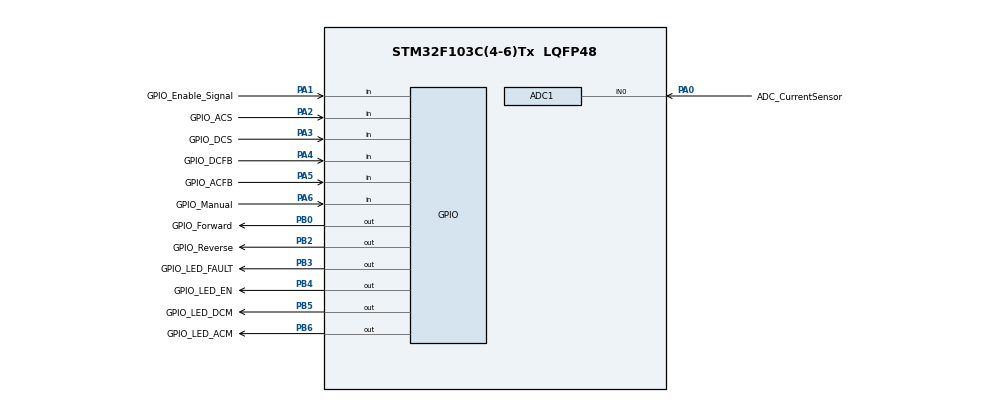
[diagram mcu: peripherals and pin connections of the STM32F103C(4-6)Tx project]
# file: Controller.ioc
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ADC1.EnableAnalogWatchDog=false
ADC1.NbrOfConversionFlag=1
ADC1.master=1
IWDG.Prescaler=IWDG_PRESCALER_64
Mcu.Family=STM32F1
Mcu.Name=STM32F103C(4-6)Tx
Mcu.Package=LQFP48
NVIC.ADC1_2_IRQn=true\:0\:0\:false\:false\:true\:true\:true\:true
NVIC.PriorityGroup=NVIC_PRIORITYGROUP_4
PA0-WKUP.GPIO_Label=ADC_CurrentSensor
PA0-WKUP.GPIO_Mode=GPIO_MODE_ANALOG
PA0-WKUP.Signal=ADCx_IN0
PA1.GPIO_Label=GPIO_Enable_Signal
PA1.Signal=GPIO_Input
PA13.Signal=SYS_JTMS-SWDIO
PA14.Signal=SYS_JTCK-SWCLK
PA15.Signal=S_TIM2_CH1_ETR
PA2.GPIO_Label=GPIO_ACS
PA2.Signal=GPIO_Input
PA3.GPIO_Label=GPIO_DCS
PA3.Signal=GPIO_Input
PA4.GPIO_Label=GPIO_DCFB
PA4.Signal=GPIO_Input
PA5.GPIO_Label=GPIO_ACFB
PA5.Signal=GPIO_Input
PA6.GPIO_Label=GPIO_Manual
PA6.Signal=GPIO_Input
PB0.GPIO_Label=GPIO_Forward
PB0.Signal=GPIO_Output
PB2.GPIO_Label=GPIO_Reverse
PB2.Signal=GPIO_Output
PB3.GPIO_Label=GPIO_LED_FAULT
PB3.Signal=GPIO_Output
PB4.GPIO_Label=GPIO_LED_EN
PB4.Signal=GPIO_Output
PB5.GPIO_Label=GPIO_LED_DCM
PB5.Signal=GPIO_Output
PB6.GPIO_Label=GPIO_LED_ACM
PB6.Signal=GPIO_Output
PD0-OSC_IN.Mode=HSE-External-Oscillator
PD0-OSC_IN.Signal=RCC_OSC_IN
PD1-OSC_OUT.Mode=HSE-External-Oscillator
PD1-OSC_OUT.Signal=RCC_OSC_OUT
ProjectManager.HeapSize=0x200
ProjectManager.StackSize=0x400
ProjectManager.TargetToolchain=STM32CubeIDE
SH.ADCx_IN0.0=ADC1_IN0,IN0
SH.S_TIM2_CH1_ETR.0=TIM2_CH1
VP_IWDG_VS_IWDG.Mode=IWDG_Activate
VP_SYS_VS_ND.Mode=No_Debug
VP_TIM2_VS_ClockSourceINT.Mode=Internal
board=custom

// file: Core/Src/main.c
/* USER CODE BEGIN Header */
/**
 ******************************************************************************
 * @file           : main.c
 * @brief          : Main program body
 ******************************************************************************
 * @attention
 *
 * Copyright (c) 2024 STMicroelectronics.
 * All rights reserved.
 *
 * This software is licensed under terms that can be found in the LICENSE file
 * in the root directory of this software component.
 * If no LICENSE file comes with this software, it is provided AS-IS.
 *
 ******************************************************************************
 */
/* USER CODE END Header */
#include "main.h"
#include "fault_handling.h"
#include "QS_Switch.h"

/* USER CODE BEGIN PTD */
// Global Variables
volatile uint32_t timer_ms = 0;
volatile uint8_t es_active = 0;
volatile uint8_t dcs_active = 0;
volatile uint8_t acs_active = 0;
volatile uint8_t fault_state = 0;
volatile uint8_t manual_mode = 0;
volatile uint8_t current_mode = 0; // 0: None, 1: DC, 2: AC

/* USER CODE END PTD */

/* USER CODE BEGIN PD */
// Function Prototypes
/* USER CODE END PD */

ADC_HandleTypeDef hadc1;

IWDG_HandleTypeDef hiwdg;

TIM_HandleTypeDef htim2;

void SystemClock_Config(void);
static void MX_GPIO_Init(void);
static void MX_ADC1_Init(void);
static void MX_TIM2_Init(void);
static void MX_IWDG_Init(void);

int main(void)
    {

    /* MCU Configuration--------------------------------------------------------*/

    /* Reset of all peripherals, Initializes the Flash interface and the Systick. */
    HAL_Init();

    /* Configure the system clock */
    SystemClock_Config();

    /* Initialize all configured peripherals */
    MX_GPIO_Init();
    MX_ADC1_Init();
    MX_TIM2_Init();
    MX_IWDG_Init();
    HAL_GPIO_WritePin(GPIOB, GPIO_LED_EN_Pin, GPIO_PIN_SET);
    /* Infinite loop */
    while (1)
	{
	RunQSLoop();
	}
    }

void SystemClock_Config(void)
    {
    RCC_OscInitTypeDef RCC_OscInitStruct =
	{
	0
	};
    RCC_ClkInitTypeDef RCC_ClkInitStruct =
	{
	0
	};
    RCC_PeriphCLKInitTypeDef PeriphClkInit =
	{
	0
	};

    /** Initializes the RCC Oscillators according to the specified parameters
     * in the RCC_OscInitTypeDef structure.
     */
    RCC_OscInitStruct.OscillatorType = RCC_OSCILLATORTYPE_HSI
	    | RCC_OSCILLATORTYPE_LSI;
    RCC_OscInitStruct.HSIState = RCC_HSI_ON;
    RCC_OscInitStruct.HSICalibrationValue = RCC_HSICALIBRATION_DEFAULT;
    RCC_OscInitStruct.LSIState = RCC_LSI_ON;
    RCC_OscInitStruct.PLL.PLLState = RCC_PLL_NONE;
    if (HAL_RCC_OscConfig(&RCC_OscInitStruct) != HAL_OK)
	{
	Error_Handler();
	}

    /** Initializes the CPU, AHB and APB buses clocks
     */
    RCC_ClkInitStruct.ClockType = RCC_CLOCKTYPE_HCLK | RCC_CLOCKTYPE_SYSCLK
	    | RCC_CLOCKTYPE_PCLK1 | RCC_CLOCKTYPE_PCLK2;
    RCC_ClkInitStruct.SYSCLKSource = RCC_SYSCLKSOURCE_HSI;
    RCC_ClkInitStruct.AHBCLKDivider = RCC_SYSCLK_DIV1;
    RCC_ClkInitStruct.APB1CLKDivider = RCC_HCLK_DIV1;
    RCC_ClkInitStruct.APB2CLKDivider = RCC_HCLK_DIV1;

    if (HAL_RCC_ClockConfig(&RCC_ClkInitStruct, FLASH_LATENCY_0) != HAL_OK)
	{
	Error_Handler();
	}
    PeriphClkInit.PeriphClockSelection = RCC_PERIPHCLK_ADC;
    PeriphClkInit.AdcClockSelection = RCC_ADCPCLK2_DIV2;
    if (HAL_RCCEx_PeriphCLKConfig(&PeriphClkInit) != HAL_OK)
	{
	Error_Handler();
	}
    }

static void MX_ADC1_Init(void)
    {

    /** Common config
     */
    hadc1.Instance = ADC1;
    hadc1.Init.ScanConvMode = ADC_SCAN_DISABLE;
    hadc1.Init.ContinuousConvMode = DISABLE;
    hadc1.Init.DiscontinuousConvMode = DISABLE;
    hadc1.Init.ExternalTrigConv = ADC_SOFTWARE_START;
    hadc1.Init.DataAlign = ADC_DATAALIGN_RIGHT;
    hadc1.Init.NbrOfConversion = 1;
    if (HAL_ADC_Init(&hadc1) != HAL_OK)
	{
	Error_Handler();
	}

    }

static void MX_IWDG_Init(void)
    {

    hiwdg.Instance = IWDG;
    hiwdg.Init.Prescaler = IWDG_PRESCALER_64;
    hiwdg.Init.Reload = 4095;
    if (HAL_IWDG_Init(&hiwdg) != HAL_OK)
	{
	Error_Handler();
	}

    }

static void MX_TIM2_Init(void)
    {

    TIM_ClockConfigTypeDef sClockSourceConfig =
	{
	0
	};
    TIM_MasterConfigTypeDef sMasterConfig =
	{
	0
	};

    htim2.Instance = TIM2;
    htim2.Init.Prescaler = 0;
    htim2.Init.CounterMode = TIM_COUNTERMODE_UP;
    htim2.Init.Period = 65535;
    htim2.Init.ClockDivision = TIM_CLOCKDIVISION_DIV1;
    htim2.Init.AutoReloadPreload = TIM_AUTORELOAD_PRELOAD_DISABLE;
    if (HAL_TIM_Base_Init(&htim2) != HAL_OK)
	{
	Error_Handler();
	}
    sClockSourceConfig.ClockSource = TIM_CLOCKSOURCE_INTERNAL;
    if (HAL_TIM_ConfigClockSource(&htim2, &sClockSourceConfig) != HAL_OK)
	{
	Error_Handler();
	}
    sMasterConfig.MasterOutputTrigger = TIM_TRGO_RESET;
    sMasterConfig.MasterSlaveMode = TIM_MASTERSLAVEMODE_DISABLE;
    if (HAL_TIMEx_MasterConfigSynchronization(&htim2, &sMasterConfig) != HAL_OK)
	{
	Error_Handler();
	}

    }

static void MX_GPIO_Init(void)
    {
    GPIO_InitTypeDef GPIO_InitStruct =
	{
	0
	};

    /* GPIO Ports Clock Enable */
    __HAL_RCC_GPIOD_CLK_ENABLE();
    __HAL_RCC_GPIOA_CLK_ENABLE();
    __HAL_RCC_GPIOB_CLK_ENABLE();

    /*Configure GPIO pin Output Level */
    HAL_GPIO_WritePin(GPIOB,
	    GPIO_Forward_Pin | GPIO_Reverse_Pin | GPIO_LED_FAULT_Pin
		    | GPIO_LED_EN_Pin | GPIO_LED_DCM_Pin | GPIO_LED_ACM_Pin,
	    GPIO_PIN_RESET);

    /*Configure GPIO pins : GPIO_Enable_Signal_Pin GPIO_ACS_Pin GPIO_DCS_Pin GPIO_DCFB_Pin
     GPIO_ACFB_Pin GPIO_Manual_Pin */
    GPIO_InitStruct.Pin = GPIO_Enable_Signal_Pin | GPIO_ACS_Pin | GPIO_DCS_Pin
	    | GPIO_DCFB_Pin | GPIO_ACFB_Pin | GPIO_Manual_Pin;
    GPIO_InitStruct.Mode = GPIO_MODE_INPUT;
    GPIO_InitStruct.Pull = GPIO_NOPULL;
    HAL_GPIO_Init(GPIOA, &GPIO_InitStruct);

    /*Configure GPIO pins : GPIO_Forward_Pin GPIO_Reverse_Pin GPIO_LED_FAULT_Pin GPIO_LED_EN_Pin
     GPIO_LED_DCM_Pin GPIO_LED_ACM_Pin */
    GPIO_InitStruct.Pin = GPIO_Forward_Pin | GPIO_Reverse_Pin
	    | GPIO_LED_FAULT_Pin | GPIO_LED_EN_Pin | GPIO_LED_DCM_Pin
	    | GPIO_LED_ACM_Pin;
    GPIO_InitStruct.Mode = GPIO_MODE_OUTPUT_PP;
    GPIO_InitStruct.Pull = GPIO_NOPULL;
    GPIO_InitStruct.Speed = GPIO_SPEED_FREQ_LOW;
    HAL_GPIO_Init(GPIOB, &GPIO_InitStruct);

    }

void Error_Handler(void)
    {
    __disable_irq();
    while (1)
	{
	}
    }
